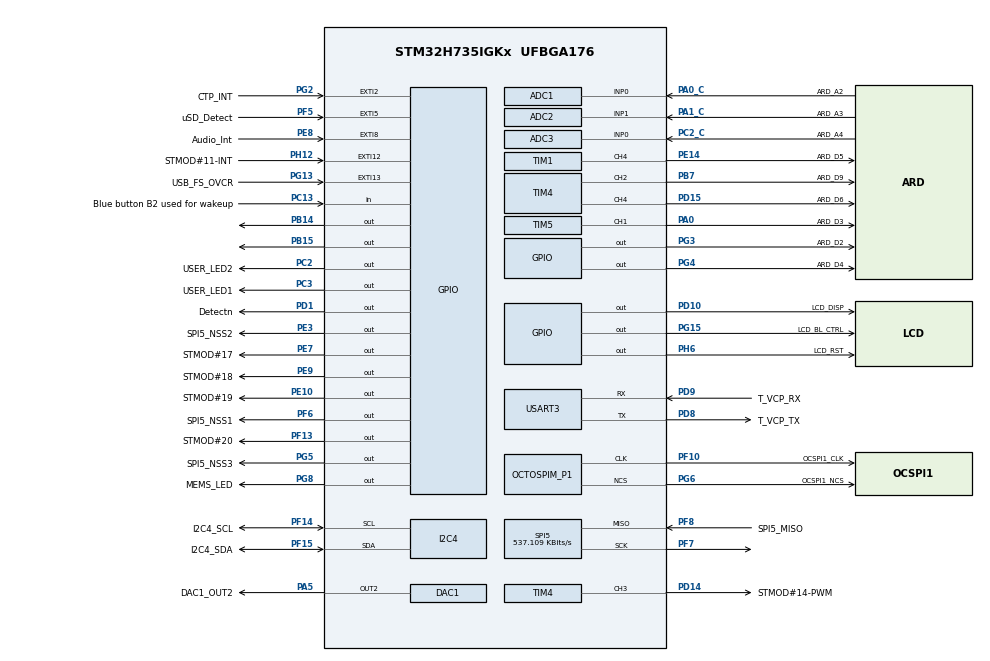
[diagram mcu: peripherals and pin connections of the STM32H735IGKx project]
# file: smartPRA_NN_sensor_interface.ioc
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ADC1.Channel-2\#ChannelRegularConversion=ADC_CHANNEL_0
ADC1.NbrOfConversionFlag=1
ADC1.OffsetNumber-2\#ChannelRegularConversion=ADC_OFFSET_NONE
ADC1.OffsetSignedSaturation-2\#ChannelRegularConversion=DISABLE
ADC1.Rank-2\#ChannelRegularConversion=1
ADC1.Resolution=ADC_RESOLUTION_10B
ADC1.SamplingTime-2\#ChannelRegularConversion=ADC_SAMPLETIME_1CYCLE_5
ADC1.master=1
ADC2.Channel-1\#ChannelRegularConversion=ADC_CHANNEL_1
ADC2.ClockPrescaler=ADC_CLOCK_ASYNC_DIV1
ADC2.NbrOfConversionFlag=1
ADC2.OffsetNumber-1\#ChannelRegularConversion=ADC_OFFSET_NONE
ADC2.OffsetSignedSaturation-1\#ChannelRegularConversion=DISABLE
ADC2.Rank-1\#ChannelRegularConversion=1
ADC2.SamplingTime-1\#ChannelRegularConversion=ADC_SAMPLETIME_1CYCLE_5
ADC3.Channel-2\#ChannelRegularConversion=ADC_CHANNEL_0
ADC3.DiscontinuousConvMode=ENABLE
ADC3.NbrOfConversionFlag=1
ADC3.OffsetNumber-2\#ChannelRegularConversion=ADC_OFFSET_NONE
ADC3.OffsetSaturation-2\#ChannelRegularConversion=DISABLE
ADC3.OffsetSign-2\#ChannelRegularConversion=ADC3_OFFSET_SIGN_NEGATIVE
ADC3.OffsetSignedSaturation-2\#ChannelRegularConversion=DISABLE
ADC3.Rank-2\#ChannelRegularConversion=1
ADC3.SamplingTime-2\#ChannelRegularConversion=ADC3_SAMPLETIME_640CYCLES_5
DAC1.DAC_Channel-DAC_OUT2=DAC_CHANNEL_2
I2C4.Timing=0x60404E72
Mcu.Family=STM32H7
Mcu.Name=STM32H735IGKx
Mcu.Package=UFBGA176
NVIC.PriorityGroup=NVIC_PRIORITYGROUP_4
NVIC.SPI5_IRQn=true\:0\:0\:true\:false\:true\:true\:true
NVIC.TIM8_UP_TIM13_IRQn=true\:1\:0\:true\:false\:true\:true\:true
NVIC.USART3_IRQn=true\:0\:0\:true\:false\:true\:true\:true
PA0.GPIO_Label=ARD_D3
PA0.Signal=S_TIM5_CH1
PA0_C.GPIO_Label=ARD_A2
PA0_C.Signal=ADCx_INP0
PA1.GPIO_Label=RMII_REF_CLK
PA1.GPIO_Speed=GPIO_SPEED_FREQ_LOW
PA1.Signal=ETH_REF_CLK
PA10.GPIO_Label=USB_FS_ID
PA10.Signal=USB_OTG_HS_ID
PA11.GPIO_Label=USB_FS_DM
PA11.Signal=USB_OTG_HS_DM
PA12.GPIO_Label=USB_FS_DP
PA12.Signal=USB_OTG_HS_DP
PA13(JTMS/SWDIO).GPIO_Label=JTMS
PA13(JTMS/SWDIO).Mode=JTAG_5_pins
PA13(JTMS/SWDIO).Signal=DEBUG_JTMS-SWDIO
PA14(JTCK/SWCLK).GPIO_Label=JTCK
PA14(JTCK/SWCLK).Mode=JTAG_5_pins
PA14(JTCK/SWCLK).Signal=DEBUG_JTCK-SWCLK
PA15(JTDI).GPIO_Label=JTDI
PA15(JTDI).Mode=JTAG_5_pins
PA15(JTDI).Signal=DEBUG_JTDI
PA1_C.GPIO_Label=ARD_A3
PA1_C.Signal=ADCx_INP1
PA2.GPIO_Label=RMII_MDIO
PA2.GPIO_Speed=GPIO_SPEED_FREQ_LOW
PA2.Signal=ETH_MDIO
PA3.GPIO_Label=LCD_B5
PA3.GPIO_Speed=GPIO_SPEED_FREQ_LOW
PA3.Signal=LTDC_B5
PA4.GPIO_Label=LCD_VSYNC
PA4.GPIO_Speed=GPIO_SPEED_FREQ_LOW
PA4.Signal=LTDC_VSYNC
PA5.GPIO_Label=DAC1_OUT2
PA5.Signal=COMP_DAC12_group
PA6.GPIO_Label=LCD_G2
PA6.GPIO_Speed=GPIO_SPEED_FREQ_LOW
PA6.Signal=LTDC_G2
PA7.GPIO_Label=RMII_CRS_DV
PA7.GPIO_Speed=GPIO_SPEED_FREQ_LOW
PA7.Signal=ETH_CRS_DV
PA8.GPIO_Label=LCD_B3
PA8.GPIO_Speed=GPIO_SPEED_FREQ_LOW
PA8.Signal=LTDC_B3
PA9.GPIO_Label=USB_FS_VBUS
PA9.Signal=USB_OTG_HS_VBUS
PB0.GPIO_Label=LCD_G1
PB0.GPIO_Speed=GPIO_SPEED_FREQ_LOW
PB0.Signal=LTDC_G1
PB1.GPIO_Label=LCD_G0
PB1.GPIO_Speed=GPIO_SPEED_FREQ_LOW
PB1.Signal=LTDC_G0
PB10.GPIO_Label=RMII_RX_ER
PB10.Signal=ETH_RX_ER
PB11.GPIO_Label=RMII_TX_EN
PB11.GPIO_Speed=GPIO_SPEED_FREQ_LOW
PB11.Signal=ETH_TX_EN
PB12.GPIO_Label=RMII_TXD0
PB12.GPIO_Speed=GPIO_SPEED_FREQ_LOW
PB12.Signal=ETH_TXD0
PB13.GPIO_Label=RMII_TXD1
PB13.GPIO_Speed=GPIO_SPEED_FREQ_LOW
PB13.Signal=ETH_TXD1
PB14.GPIO_ModeDefaultOutputPP=GPIO_MODE_OUTPUT_PP
PB14.Signal=GPIO_Output
PB15.Signal=GPIO_Output
PB2.GPIO_Label=OCSPI1_DQS
PB2.Signal=OCTOSPIM_P1_DQS
PB3(JTDO/TRACESWO).GPIO_Label=JTDO
PB3(JTDO/TRACESWO).Mode=JTAG_5_pins
PB3(JTDO/TRACESWO).Signal=DEBUG_JTDO-SWO
PB4(NJTRST).GPIO_Label=NJTRST
PB4(NJTRST).Mode=JTAG_5_pins
PB4(NJTRST).Signal=DEBUG_JTRST
PB5.GPIO_Label=FDCAN2_RX
PB5.Signal=FDCAN2_RX
PB6.GPIO_Label=FDCAN2_TX
PB6.Signal=FDCAN2_TX
PB7.GPIO_Label=ARD_D9
PB7.Signal=S_TIM4_CH2
PB8.GPIO_Label=LCD_B6
PB8.GPIO_Speed=GPIO_SPEED_FREQ_LOW
PB8.Signal=LTDC_B6
PB9.GPIO_Label=LCD_B7
PB9.GPIO_Speed=GPIO_SPEED_FREQ_LOW
PB9.Signal=LTDC_B7
PC0.GPIO_Label=ARD_A0
PC0.Signal=ADCx_INP10
PC1.GPIO_Label=RMII_MDC
PC1.GPIO_Speed=GPIO_SPEED_FREQ_LOW
PC1.Signal=ETH_MDC
PC10.GPIO_Label=SDIO1_D2
PC10.Signal=SDMMC1_D2
PC11.GPIO_Label=SDIO1_D3
PC11.Signal=SDMMC1_D3
PC12.GPIO_Label=SDIO1_CK
PC12.Signal=SDMMC1_CK
PC13.GPIO_Label=Blue button B2 used for wakeup
PC13.Signal=GPIO_Input
PC14-OSC32_IN.Mode=LSE-External-Oscillator
PC14-OSC32_IN.Signal=RCC_OSC32_IN
PC15-OSC32_OUT.Mode=LSE-External-Oscillator
PC15-OSC32_OUT.Signal=RCC_OSC32_OUT
PC2.GPIO_Label=USER_LED2
PC2.Signal=GPIO_Output
PC2_C.GPIO_Label=ARD_A4
PC2_C.Mode=IN0-Single-Ended
PC2_C.Signal=ADC3_INP0
PC3.GPIO_Label=USER_LED1
PC3.Signal=GPIO_Output
PC3_C.GPIO_Label=ARD_A5
PC3_C.Signal=ADC3_INP1
PC4.GPIO_Label=RMII_RXD0
PC4.GPIO_Speed=GPIO_SPEED_FREQ_LOW
PC4.Signal=ETH_RXD0
PC5.GPIO_Label=RMII_RXD1
PC5.GPIO_Speed=GPIO_SPEED_FREQ_LOW
PC5.Signal=ETH_RXD1
PC6.GPIO_Label=LCD_HSYNC
PC6.GPIO_Speed=GPIO_SPEED_FREQ_LOW
PC6.Signal=LTDC_HSYNC
PC7.GPIO_Label=LCD_G6
PC7.GPIO_Speed=GPIO_SPEED_FREQ_LOW
PC7.Signal=LTDC_G6
PC8.GPIO_Label=SDIO1_D0
PC8.Signal=SDMMC1_D0
PC9.GPIO_Label=SDIO1_D1
PC9.Signal=SDMMC1_D1
PD0.GPIO_Label=LCD_B1
PD0.GPIO_Speed=GPIO_SPEED_FREQ_LOW
PD0.Signal=LTDC_B1
PD1.GPIO_Label=Detectn
PD1.GPIO_PuPd=GPIO_NOPULL
PD1.Signal=GPIO_Output
PD10.GPIO_Label=LCD_DISP
PD10.GPIO_Speed=GPIO_SPEED_FREQ_LOW
PD10.Signal=GPIO_Output
PD12.GPIO_Label=OCSPI1_IO1
PD12.Signal=OCTOSPIM_P1_IO1
PD13.GPIO_Label=OCSPI1_IO3
PD13.Signal=OCTOSPIM_P1_IO3
PD14.GPIO_Label=STMOD\#14-PWM
PD14.Signal=S_TIM4_CH3
PD15.GPIO_Label=ARD_D6
PD15.Signal=S_TIM4_CH4
PD2.GPIO_Label=SDIO1_CMD
PD2.Signal=SDMMC1_CMD
PD3.GPIO_Label=LCD_G7
PD3.GPIO_Speed=GPIO_SPEED_FREQ_LOW
PD3.Signal=LTDC_G7
PD4.GPIO_Label=OCSPI1_IO4
PD4.Signal=OCTOSPIM_P1_IO4
PD5.GPIO_Label=OCSPI1_IO5
PD5.Signal=OCTOSPIM_P1_IO5
PD6.GPIO_Label=LCD_B2
PD6.GPIO_Speed=GPIO_SPEED_FREQ_LOW
PD6.Signal=LTDC_B2
PD7.GPIO_Label=OCSPI1_IO7
PD7.Signal=OCTOSPIM_P1_IO7
PD8.GPIO_Label=T_VCP_TX
PD8.GPIO_PuPd=GPIO_NOPULL
PD8.Mode=Asynchronous
PD8.Signal=USART3_TX
PD9.GPIO_Label=T_VCP_RX
PD9.GPIO_PuPd=GPIO_NOPULL
PD9.Mode=Asynchronous
PD9.Signal=USART3_RX
PE0.GPIO_Label=LCD_R0
PE0.GPIO_Speed=GPIO_SPEED_FREQ_LOW
PE0.Signal=LTDC_R0
PE1.GPIO_Label=LCD_R6
PE1.GPIO_Speed=GPIO_SPEED_FREQ_LOW
PE1.Signal=LTDC_R6
PE10.GPIO_Label=STMOD\#19
PE10.Signal=GPIO_Output
PE11.GPIO_Label=LCD_G3
PE11.GPIO_Speed=GPIO_SPEED_FREQ_LOW
PE11.Signal=LTDC_G3
PE12.GPIO_Label=LCD_B4
PE12.GPIO_Speed=GPIO_SPEED_FREQ_LOW
PE12.Signal=LTDC_B4
PE13.GPIO_Label=LCD_DE
PE13.GPIO_Speed=GPIO_SPEED_FREQ_LOW
PE13.Signal=LTDC_DE
PE14.GPIO_Label=ARD_D5
PE14.Signal=S_TIM1_CH4
PE15.GPIO_Label=LCD_R7
PE15.GPIO_Speed=GPIO_SPEED_FREQ_LOW
PE15.Signal=LTDC_R7
PE2.GPIO_Label=OCSPI1_IO2
PE2.Signal=OCTOSPIM_P1_IO2
PE3.GPIO_Label=SPI5_NSS2
PE3.Signal=GPIO_Output
PE4.GPIO_Label=SAI4_D2
PE4.Signal=SAI4_D2
PE5.GPIO_Label=SAI4_CK2
PE5.Signal=SAI4_CK2
PE6.GPIO_Label=SAI1_SD_A
PE6.Signal=SAI1_SD_A
PE7.GPIO_Label=STMOD\#17
PE7.Signal=GPIO_Output
PE8.GPIO_Label=Audio_Int
PE8.Signal=GPXTI8
PE9.GPIO_Label=STMOD\#18
PE9.Signal=GPIO_Output
PF0.GPIO_Label=OCSPI2_IO0
PF0.Signal=OCTOSPIM_P2_IO0
PF1.GPIO_Label=OCSPI2_IO1
PF1.Signal=OCTOSPIM_P2_IO1
PF10.GPIO_Label=OCSPI1_CLK
PF10.Mode=O1_P1_CLK
PF10.Signal=OCTOSPIM_P1_CLK
PF12.GPIO_Label=OCSPI2_DQS
PF12.Signal=OCTOSPIM_P2_DQS
PF13.GPIO_Label=STMOD\#20
PF13.Signal=GPIO_Output
PF14.GPIO_Label=I2C4_SCL
PF14.GPIO_Pu=GPIO_PULLUP
PF14.Mode=I2C
PF14.Signal=I2C4_SCL
PF15.GPIO_Label=I2C4_SDA
PF15.GPIO_Pu=GPIO_PULLUP
PF15.Mode=I2C
PF15.Signal=I2C4_SDA
PF2.GPIO_Label=OCSPI2_IO2
PF2.Signal=OCTOSPIM_P2_IO2
PF3.GPIO_Label=OCSPI2_IO3
PF3.Signal=OCTOSPIM_P2_IO3
PF4.GPIO_Label=OCSPI2_CLK
PF4.Signal=OCTOSPIM_P2_CLK
PF5.GPIO_Label=uSD_Detect
PF5.Signal=GPXTI5
PF6.GPIO_Label=SPI5_NSS1
PF6.Signal=GPIO_Output
PF7.GPIO_PuPd=GPIO_PULLUP
PF7.Mode=RX_Only_Simplex_Unidirect_Master
PF7.Signal=SPI5_SCK
PF8.GPIO_Label=SPI5_MISO
PF8.Mode=RX_Only_Simplex_Unidirect_Master
PF8.Signal=SPI5_MISO
PG0.GPIO_Label=OCSPI2_IO4
PG0.Signal=OCTOSPIM_P2_IO4
PG1.GPIO_Label=OCSPI2_IO5
PG1.Signal=OCTOSPIM_P2_IO5
PG10.GPIO_Label=OCSPI2_IO6
PG10.Signal=OCTOSPIM_P2_IO6
PG11.GPIO_Label=OCSPI2_IO7
PG11.Signal=OCTOSPIM_P2_IO7
PG12.GPIO_Label=OCSPI2_NCS
PG12.Signal=OCTOSPIM_P2_NCS
PG13.GPIO_Label=USB_FS_OVCR
PG13.Signal=GPXTI13
PG14.GPIO_Label=LCD_B0
PG14.GPIO_Speed=GPIO_SPEED_FREQ_LOW
PG14.Signal=LTDC_B0
PG15.GPIO_Label=LCD_BL_CTRL
PG15.GPIO_Speed=GPIO_SPEED_FREQ_LOW
PG15.Signal=GPIO_Output
PG2.GPIO_Label=CTP_INT
PG2.Signal=GPXTI2
PG3.GPIO_Label=ARD_D2
PG3.Signal=GPIO_Output
PG4.GPIO_Label=ARD_D4
PG4.Signal=GPIO_Output
PG5.GPIO_Label=SPI5_NSS3
PG5.Signal=GPIO_Output
PG6.GPIO_Label=OCSPI1_NCS
PG6.Mode=OCTOSPI1_Port1_NCS
PG6.Signal=OCTOSPIM_P1_NCS
PG7.GPIO_Label=LCD_CLK
PG7.GPIO_Speed=GPIO_SPEED_FREQ_LOW
PG7.Signal=LTDC_CLK
PG8.GPIO_Label=MEMS_LED
PG8.Signal=GPIO_Output
PG9.GPIO_Label=OCSPI1_IO6
PG9.Signal=OCTOSPIM_P1_IO6
PH0-OSC_IN.Mode=HSE-External-Oscillator
PH0-OSC_IN.Signal=RCC_OSC_IN
PH1-OSC_OUT.Mode=HSE-External-Oscillator
PH1-OSC_OUT.Signal=RCC_OSC_OUT
PH10.GPIO_Label=LCD_R4
PH10.GPIO_Speed=GPIO_SPEED_FREQ_LOW
PH10.Signal=LTDC_R4
PH11.GPIO_Label=LCD_R5
PH11.GPIO_Speed=GPIO_SPEED_FREQ_LOW
PH11.Signal=LTDC_R5
PH12.GPIO_Label=STMOD\#11-INT
PH12.Signal=GPXTI12
PH13.GPIO_Label=FDCAN1_TX
PH13.Signal=FDCAN1_TX
PH14.GPIO_Label=FDCAN1_RX
PH14.Signal=FDCAN1_RX
PH15.GPIO_Label=LCD_G4
PH15.GPIO_Speed=GPIO_SPEED_FREQ_LOW
PH15.Signal=LTDC_G4
PH2.GPIO_Label=ARD_A1
PH2.Signal=ADC3_INP13
PH3.GPIO_Label=LCD_R1
PH3.GPIO_Speed=GPIO_SPEED_FREQ_LOW
PH3.Signal=LTDC_R1
PH4.GPIO_Label=LCD_G5
PH4.GPIO_Speed=GPIO_SPEED_FREQ_LOW
PH4.Signal=LTDC_G5
PH6.GPIO_Label=LCD_RST
PH6.GPIO_Speed=GPIO_SPEED_FREQ_LOW
PH6.Signal=GPIO_Output
PH8.GPIO_Label=LCD_R2
PH8.GPIO_Speed=GPIO_SPEED_FREQ_LOW
PH8.Signal=LTDC_R2
PH9.GPIO_Label=LCD_R3
PH9.GPIO_Speed=GPIO_SPEED_FREQ_LOW
PH9.Signal=LTDC_R3
ProjectManager.HeapSize=0x200
ProjectManager.StackSize=0x400
ProjectManager.TargetToolchain=STM32CubeIDE
RCC.ADCFreq_Value=80000000
RCC.APB1Freq_Value=137500000
RCC.APB2Freq_Value=137500000
RCC.APB3Freq_Value=137500000
RCC.APB4Freq_Value=137500000
RCC.CortexFreq_Value=550000000
RCC.D1PPRE=RCC_APB3_DIV2
RCC.D2PPRE1=RCC_APB1_DIV2
RCC.D2PPRE2=RCC_APB2_DIV2
RCC.D3PPRE=RCC_APB4_DIV2
RCC.DIVM1=5
RCC.DIVM2=5
RCC.DIVN1=110
RCC.DIVN2=80
RCC.DIVP1=1
RCC.DIVP2=5
RCC.DIVQ1=4
RCC.HCLKFreq_Value=275000000
RCC.HPRE=RCC_HCLK_DIV2
RCC.PLL1_VCI_Range-AdvancedSettings=RCC_PLL1VCIRANGE_3
RCC.PLL1_VCO_SEL-AdvancedSettings=RCC_PLL1VCOMEDIUM
RCC.PLL2FRACN=0
RCC.PLL2_VCI_Range-AdvancedSettings=RCC_PLL2VCIRANGE_0
RCC.PLL2_VCO_SEL-AdvancedSettings=RCC_PLL2VCOMEDIUM
RCC.PLL3FRACN=0
RCC.PLL3_VCO_SEL-AdvancedSettings=RCC_PLL3VCOMEDIUM
RCC.PLLFRACN=0
RCC.PLLSourceVirtual=RCC_PLLSOURCE_HSE
RCC.SYSCLKFreq_VALUE=550000000
RCC.SYSCLKSource=RCC_SYSCLKSOURCE_PLLCLK
RCC.USBCLockSelection=RCC_USBCLKSOURCE_HSI48
RCC.USBFreq_Value=48000000
SH.ADCx_INP0.0=ADC1_INP0,IN0-Single-Ended
SH.ADCx_INP1.0=ADC2_INP1,IN1-Single-Ended
SH.ADCx_INP10.0=ADC1_INP10
SH.COMP_DAC12_group.0=DAC1_OUT2,DAC_OUT2
SH.S_TIM1_CH4.0=TIM1_CH4,PWM Generation4 CH4
SH.S_TIM4_CH2.0=TIM4_CH2,PWM Generation2 CH2
SH.S_TIM4_CH3.0=TIM4_CH3,PWM Generation3 CH3
SH.S_TIM4_CH4.0=TIM4_CH4,PWM Generation4 CH4
SH.S_TIM5_CH1.0=TIM5_CH1,PWM Generation1 CH1
SPI5.BaudRatePrescaler=SPI_BAUDRATEPRESCALER_256
SPI5.CalculateBaudRate=537.109 KBits/s
SPI5.DataSize=SPI_DATASIZE_16BIT
SPI5.Direction=SPI_DIRECTION_2LINES_RXONLY
SPI5.Mode=SPI_MODE_MASTER
SPI5.VirtualType=VM_MASTER
TIM1.Channel-PWM\ Generation4\ CH4=TIM_CHANNEL_4
TIM13.AutoReloadPreload=TIM_AUTORELOAD_PRELOAD_ENABLE
TIM13.Period=1000-1
TIM13.Prescaler=275 - 1
TIM4.Channel-PWM\ Generation2\ CH2=TIM_CHANNEL_2
TIM4.Channel-PWM\ Generation3\ CH3=TIM_CHANNEL_3
TIM4.Channel-PWM\ Generation4\ CH4=TIM_CHANNEL_4
TIM5.Channel-PWM\ Generation1\ CH1=TIM_CHANNEL_1
USART3.VirtualMode-Asynchronous=VM_ASYNC
VP_OCTOSPI1_VS_dual.Mode=single_mode
VP_TIM13_VS_ClockSourceINT.Mode=Enable_Timer
board=STM32H735G-DK

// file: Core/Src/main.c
/* USER CODE BEGIN Header */
/**
  ******************************************************************************
  * @file           : main.c
  * @brief          : Main program body
  ******************************************************************************
  * @attention
  *
  * <h2><center>&copy; Copyright (c) 2021 STMicroelectronics.
  * All rights reserved.</center></h2>
  *
  * This software component is licensed by ST under BSD 3-Clause license,
  * the "License"; You may not use this file except in compliance with the
  * License. You may obtain a copy of the License at:
  *                        opensource.org/licenses/BSD-3-Clause
  *
  ******************************************************************************
  */
/* USER CODE END Header */
#include "main.h"

/* USER CODE BEGIN Includes */
#include "neuralnet.h"
#include "nnconfig.h"
/* USER CODE END Includes */

/* USER CODE BEGIN PD */
#ifdef __GNUC__
/* With GCC, small printf (option LD Linker->Libraries->Small printf
   set to 'Yes') calls __io_putchar() */
#define PUTCHAR_PROTOTYPE int __io_putchar(int ch)
#else
#define PUTCHAR_PROTOTYPE int fputc(int ch, FILE *f)
#endif /* __GNUC__ */
/* USER CODE END PD */

ADC_HandleTypeDef hadc1;
ADC_HandleTypeDef hadc2;
ADC_HandleTypeDef hadc3;

DAC_HandleTypeDef hdac1;

I2C_HandleTypeDef hi2c4;

OSPI_HandleTypeDef hospi1;

SPI_HandleTypeDef hspi5;

TIM_HandleTypeDef htim1;
TIM_HandleTypeDef htim4;
TIM_HandleTypeDef htim5;
TIM_HandleTypeDef htim13;

UART_HandleTypeDef huart3;

/* USER CODE BEGIN PV */

PUTCHAR_PROTOTYPE
{
  /* Place your implementation of fputc here */
  /* e.g. write a character to the USART1 and Loop until the end of transmission */
  HAL_UART_Transmit(&huart3, (uint8_t *)&ch, 1, 0xFFFF);

  return ch;
}
/* USER CODE END PV */

void SystemClock_Config(void);
void PeriphCommonClock_Config(void);
static void MX_GPIO_Init(void);
static void MX_ADC1_Init(void);
static void MX_ADC3_Init(void);
static void MX_DAC1_Init(void);
static void MX_I2C4_Init(void);
static void MX_OCTOSPI1_Init(void);
static void MX_TIM1_Init(void);
static void MX_TIM4_Init(void);
static void MX_TIM5_Init(void);
static void MX_USART3_UART_Init(void);
static void MX_SPI5_Init(void);
static void MX_TIM13_Init(void);
static void MX_ADC2_Init(void);
/* USER CODE BEGIN PFP */

//Sensor Data Buffer
float voltage_value = 0;
float temp_value = 0 ;
float current_value = 0;
uint16_t buffer_rx1;
_Bool flag_current, flag;
uint32_t adc_value2;

//Counter Variables
uint16_t counter = 0;
uint32_t start, end;
uint32_t start_, end_;
uint32_t counter_for_timing = 0;

//average responsive time Variables
uint32_t temp_exec = 0;
uint32_t voltage_exec = 0;
uint32_t current_exec = 0;
uint32_t NN_exec = 0;
uint32_t Total_exec = 0;

// Neural Net Model Variables
Model* model;
Linear* l1;;
Linear* l2;
Linear* l3;

//
#define DATA_DEBUG 1
#define TIME_DEBUG 1
/* USER CODE END PFP */

/* USER CODE BEGIN 0 */
void print_data(){

	printf("--------------------\r\n");
	printf("Voltage : %f(V)\r\n", voltage_value);
	printf("temperature : %f('C)\r\n", temp_value);
	printf("ADC value : %ld -> current : %f(mA)\r\n", adc_value2, current_value);
}

void HAL_SPI_RxCpltCallback(SPI_HandleTypeDef *hspi)
{
	HAL_GPIO_WritePin(SPI5_NSS1_GPIO_Port, SPI5_NSS1_Pin, GPIO_PIN_SET); // deactivate
	flag = 1;
	current_value = (buffer_rx1 - 2048) * 1000 / 89.95;
}

//Timer interrupted every 1ms
void HAL_TIM_PeriodElapsedCallback(TIM_HandleTypeDef *htim)
{

	uint32_t adc_value;

	uint16_t print_interval = 100;

	if (htim->Instance == TIM13)
	{
		start = htim->Instance->CNT;
		counter_for_timing++;

		counter = (counter + 1) % print_interval;

		//Get Voltage sensor value
		start_ = htim->Instance->CNT;
		HAL_ADC_Start(&hadc1);
		HAL_ADC_PollForConversion(&hadc1, 1);
		adc_value = HAL_ADC_GetValue(&hadc1);
		HAL_ADC_Stop(&hadc1);
		end_ = htim->Instance->CNT;

		voltage_exec += (end_ - start_);

		voltage_value =  (float)(adc_value - 37) * 5 * 4 / 1024;

		//Get temperature sensor value
		start_ = htim->Instance->CNT;
		HAL_ADC_Start(&hadc3);
		HAL_ADC_PollForConversion(&hadc3, 1);
		adc_value = HAL_ADC_GetValue(&hadc3);
		HAL_ADC_Stop(&hadc3);
		end_ = htim->Instance->CNT;
		temp_exec += (end_ - start_);

		temp_value = (float)(adc_value *330) / 4095;

		//Get current sensor value
		start_ = htim->Instance->CNT;
		HAL_ADC_Start(&hadc2);
		HAL_ADC_PollForConversion(&hadc2, 1);
		adc_value2 = HAL_ADC_GetValue(&hadc2);
		HAL_ADC_Stop(&hadc2);
		current_value = (float)(adc_value2* 3.3) / 65535 ;

		end_ = htim->Instance->CNT;
		current_exec += (end_ - start_);

		start_ = htim->Instance->CNT;
		float sample[4] = {current_value, voltage_value, temp_value, 0 };
		float* result = forward(model, sample);
		end_ = htim->Instance->CNT;

		NN_exec += (end_ - start_);

		Total_exec += (end_ - start);
		if(DATA_DEBUG){
			if(counter == 0){
				print_data();
				printf("NeuralNet Output : ");
				for (int i = 0; i < l3->out_dim; i++) {
					printf("%d : %f 	", i, result[i]);
				}
				printf("\r\n--------------------\r\n\r\n");
			}
		}

		if(TIME_DEBUG){

			if(counter_for_timing == 1000){

				printf("\r\n");
				printf("-------------------------------------\r\n");
				printf("current sensor response time : %f(us)\r\n", (float)current_exec /1000 );
				printf("ADC voltage sensor response time : %f(us)\r\n", (float)voltage_exec / 1000);
				printf("ADC temperature sensor response time : %f(us)\r\n", (float)temp_exec / 1000);
				printf("Neural Net Processing response time : %f(us)\r\n", (float)NN_exec / 1000);
				printf("Total response time : %f(us)\r\n", (float)Total_exec / 1000);
				printf("--------------------------------------\r\n\r\n");

				current_exec = 0;
				temp_exec = 0;
				voltage_exec =0;
				NN_exec =0 ;
				Total_exec = 0;
				counter_for_timing =0;
			}
		}
	}

}

/* USER CODE END 0 */

int main(void)
{

  /* MCU Configuration--------------------------------------------------------*/

  /* Reset of all peripherals, Initializes the Flash interface and the Systick. */
  HAL_Init();

  /* Configure the system clock */
  SystemClock_Config();

/* Configure the peripherals common clocks */
  PeriphCommonClock_Config();

  /* Initialize all configured peripherals */
  MX_GPIO_Init();
  MX_ADC1_Init();
  MX_ADC3_Init();
  MX_DAC1_Init();
  MX_I2C4_Init();
  MX_OCTOSPI1_Init();
  MX_TIM1_Init();
  MX_TIM4_Init();
  MX_TIM5_Init();
  MX_USART3_UART_Init();
  MX_SPI5_Init();
  MX_TIM13_Init();
  MX_ADC2_Init();

  /* Infinite loop */
  /* USER CODE BEGIN WHILE */
  HAL_GPIO_WritePin(SPI5_NSS1_GPIO_Port, SPI5_NSS1_Pin, GPIO_PIN_SET); // deactivate

  model = (Model*)malloc(sizeof(Model));
  Model_construct(model, linear_num);

  l1 = (Linear*)malloc(sizeof(Linear));
  l2 = (Linear*)malloc(sizeof(Linear));
  l3 = (Linear*)malloc(sizeof(Linear));

  Linear_construct(l1, linear1_out_dim, linear1_in_dim, linear1_bias, RELU);
  l1->weight = (float**)malloc(sizeof(float*) * linear1_out_dim);
  for (int i = 0; i < linear1_out_dim; i++) {
  	l1->weight[i] = linear1_weight[i];
  }
  Model_append(model, l1, 1);

  Linear_construct(l2, linear2_out_dim, linear2_in_dim, linear2_bias, RELU);
  l2->weight = (float**)malloc(sizeof(float*) * linear2_out_dim);
  for (int i = 0; i < linear2_out_dim; i++) {
  	l2->weight[i] = linear2_weight[i];
  }
  Model_append(model, l2, 2);

  Linear_construct(l3, linear3_out_dim, linear3_in_dim, linear3_bias, SIGMOID);
  l3->weight = (float**)malloc(sizeof(float*) * linear3_out_dim);
  for (int i = 0; i < linear3_out_dim; i++) {
	  l3->weight[i] = linear3_weight[i];
  }
  Model_append(model, l3, 3);

  HAL_TIM_Base_Start_IT(&htim13);
  while (1)
  {
    /* USER CODE END WHILE */

  }
}

void SystemClock_Config(void)
{
  RCC_OscInitTypeDef RCC_OscInitStruct = {0};
  RCC_ClkInitTypeDef RCC_ClkInitStruct = {0};

  /** Supply configuration update enable
  */
  HAL_PWREx_ConfigSupply(PWR_DIRECT_SMPS_SUPPLY);
  /** Configure the main internal regulator output voltage
  */
  __HAL_PWR_VOLTAGESCALING_CONFIG(PWR_REGULATOR_VOLTAGE_SCALE0);

  while(!__HAL_PWR_GET_FLAG(PWR_FLAG_VOSRDY)) {}
  /** Macro to configure the PLL clock source
  */
  __HAL_RCC_PLL_PLLSOURCE_CONFIG(RCC_PLLSOURCE_HSE);
  /** Initializes the RCC Oscillators according to the specified parameters
  * in the RCC_OscInitTypeDef structure.
  */
  RCC_OscInitStruct.OscillatorType = RCC_OSCILLATORTYPE_HSE;
  RCC_OscInitStruct.HSEState = RCC_HSE_ON;
  RCC_OscInitStruct.PLL.PLLState = RCC_PLL_ON;
  RCC_OscInitStruct.PLL.PLLSource = RCC_PLLSOURCE_HSE;
  RCC_OscInitStruct.PLL.PLLM = 5;
  RCC_OscInitStruct.PLL.PLLN = 110;
  RCC_OscInitStruct.PLL.PLLP = 1;
  RCC_OscInitStruct.PLL.PLLQ = 4;
  RCC_OscInitStruct.PLL.PLLR = 2;
  RCC_OscInitStruct.PLL.PLLRGE = RCC_PLL1VCIRANGE_2;
  RCC_OscInitStruct.PLL.PLLVCOSEL = RCC_PLL1VCOWIDE;
  RCC_OscInitStruct.PLL.PLLFRACN = 0;
  if (HAL_RCC_OscConfig(&RCC_OscInitStruct) != HAL_OK)
  {
    Error_Handler();
  }
  /** Initializes the CPU, AHB and APB buses clocks
  */
  RCC_ClkInitStruct.ClockType = RCC_CLOCKTYPE_HCLK|RCC_CLOCKTYPE_SYSCLK
                              |RCC_CLOCKTYPE_PCLK1|RCC_CLOCKTYPE_PCLK2
                              |RCC_CLOCKTYPE_D3PCLK1|RCC_CLOCKTYPE_D1PCLK1;
  RCC_ClkInitStruct.SYSCLKSource = RCC_SYSCLKSOURCE_PLLCLK;
  RCC_ClkInitStruct.SYSCLKDivider = RCC_SYSCLK_DIV1;
  RCC_ClkInitStruct.AHBCLKDivider = RCC_HCLK_DIV2;
  RCC_ClkInitStruct.APB3CLKDivider = RCC_APB3_DIV2;
  RCC_ClkInitStruct.APB1CLKDivider = RCC_APB1_DIV2;
  RCC_ClkInitStruct.APB2CLKDivider = RCC_APB2_DIV2;
  RCC_ClkInitStruct.APB4CLKDivider = RCC_APB4_DIV2;

  if (HAL_RCC_ClockConfig(&RCC_ClkInitStruct, FLASH_LATENCY_3) != HAL_OK)
  {
    Error_Handler();
  }
}

void PeriphCommonClock_Config(void)
{
  RCC_PeriphCLKInitTypeDef PeriphClkInitStruct = {0};

  /** Initializes the peripherals clock
  */
  PeriphClkInitStruct.PeriphClockSelection = RCC_PERIPHCLK_ADC;
  PeriphClkInitStruct.PLL2.PLL2M = 5;
  PeriphClkInitStruct.PLL2.PLL2N = 80;
  PeriphClkInitStruct.PLL2.PLL2P = 5;
  PeriphClkInitStruct.PLL2.PLL2Q = 2;
  PeriphClkInitStruct.PLL2.PLL2R = 2;
  PeriphClkInitStruct.PLL2.PLL2RGE = RCC_PLL2VCIRANGE_2;
  PeriphClkInitStruct.PLL2.PLL2VCOSEL = RCC_PLL2VCOWIDE;
  PeriphClkInitStruct.PLL2.PLL2FRACN = 0;
  PeriphClkInitStruct.AdcClockSelection = RCC_ADCCLKSOURCE_PLL2;
  if (HAL_RCCEx_PeriphCLKConfig(&PeriphClkInitStruct) != HAL_OK)
  {
    Error_Handler();
  }
}

static void MX_ADC1_Init(void)
{

  ADC_MultiModeTypeDef multimode = {0};
  ADC_ChannelConfTypeDef sConfig = {0};

  /** Common config
  */
  hadc1.Instance = ADC1;
  hadc1.Init.ClockPrescaler = ADC_CLOCK_ASYNC_DIV1;
  hadc1.Init.Resolution = ADC_RESOLUTION_10B;
  hadc1.Init.ScanConvMode = ADC_SCAN_DISABLE;
  hadc1.Init.EOCSelection = ADC_EOC_SINGLE_CONV;
  hadc1.Init.LowPowerAutoWait = DISABLE;
  hadc1.Init.ContinuousConvMode = DISABLE;
  hadc1.Init.NbrOfConversion = 1;
  hadc1.Init.DiscontinuousConvMode = DISABLE;
  hadc1.Init.ExternalTrigConv = ADC_SOFTWARE_START;
  hadc1.Init.ExternalTrigConvEdge = ADC_EXTERNALTRIGCONVEDGE_NONE;
  hadc1.Init.ConversionDataManagement = ADC_CONVERSIONDATA_DR;
  hadc1.Init.Overrun = ADC_OVR_DATA_PRESERVED;
  hadc1.Init.LeftBitShift = ADC_LEFTBITSHIFT_NONE;
  hadc1.Init.OversamplingMode = DISABLE;
  if (HAL_ADC_Init(&hadc1) != HAL_OK)
  {
    Error_Handler();
  }
  /** Configure the ADC multi-mode
  */
  multimode.Mode = ADC_MODE_INDEPENDENT;
  if (HAL_ADCEx_MultiModeConfigChannel(&hadc1, &multimode) != HAL_OK)
  {
    Error_Handler();
  }
  /** Configure Regular Channel
  */
  sConfig.Channel = ADC_CHANNEL_0;
  sConfig.Rank = ADC_REGULAR_RANK_1;
  sConfig.SamplingTime = ADC_SAMPLETIME_1CYCLE_5;
  sConfig.SingleDiff = ADC_SINGLE_ENDED;
  sConfig.OffsetNumber = ADC_OFFSET_NONE;
  sConfig.Offset = 0;
  sConfig.OffsetSignedSaturation = DISABLE;
  if (HAL_ADC_ConfigChannel(&hadc1, &sConfig) != HAL_OK)
  {
    Error_Handler();
  }

}

static void MX_ADC2_Init(void)
{

  ADC_ChannelConfTypeDef sConfig = {0};

  /** Common config
  */
  hadc2.Instance = ADC2;
  hadc2.Init.ClockPrescaler = ADC_CLOCK_ASYNC_DIV1;
  hadc2.Init.Resolution = ADC_RESOLUTION_16B;
  hadc2.Init.ScanConvMode = ADC_SCAN_DISABLE;
  hadc2.Init.EOCSelection = ADC_EOC_SINGLE_CONV;
  hadc2.Init.LowPowerAutoWait = DISABLE;
  hadc2.Init.ContinuousConvMode = DISABLE;
  hadc2.Init.NbrOfConversion = 1;
  hadc2.Init.DiscontinuousConvMode = DISABLE;
  hadc2.Init.ExternalTrigConv = ADC_SOFTWARE_START;
  hadc2.Init.ExternalTrigConvEdge = ADC_EXTERNALTRIGCONVEDGE_NONE;
  hadc2.Init.ConversionDataManagement = ADC_CONVERSIONDATA_DR;
  hadc2.Init.Overrun = ADC_OVR_DATA_PRESERVED;
  hadc2.Init.LeftBitShift = ADC_LEFTBITSHIFT_NONE;
  hadc2.Init.OversamplingMode = DISABLE;
  if (HAL_ADC_Init(&hadc2) != HAL_OK)
  {
    Error_Handler();
  }
  /** Configure Regular Channel
  */
  sConfig.Channel = ADC_CHANNEL_1;
  sConfig.Rank = ADC_REGULAR_RANK_1;
  sConfig.SamplingTime = ADC_SAMPLETIME_1CYCLE_5;
  sConfig.SingleDiff = ADC_SINGLE_ENDED;
  sConfig.OffsetNumber = ADC_OFFSET_NONE;
  sConfig.Offset = 0;
  sConfig.OffsetSignedSaturation = DISABLE;
  if (HAL_ADC_ConfigChannel(&hadc2, &sConfig) != HAL_OK)
  {
    Error_Handler();
  }

}

static void MX_ADC3_Init(void)
{

  ADC_ChannelConfTypeDef sConfig = {0};

  /** Common config
  */
  hadc3.Instance = ADC3;
  hadc3.Init.ClockPrescaler = ADC_CLOCK_ASYNC_DIV1;
  hadc3.Init.Resolution = ADC_RESOLUTION_12B;
  hadc3.Init.DataAlign = ADC3_DATAALIGN_RIGHT;
  hadc3.Init.ScanConvMode = ADC_SCAN_DISABLE;
  hadc3.Init.EOCSelection = ADC_EOC_SINGLE_CONV;
  hadc3.Init.LowPowerAutoWait = DISABLE;
  hadc3.Init.ContinuousConvMode = DISABLE;
  hadc3.Init.NbrOfConversion = 1;
  hadc3.Init.DiscontinuousConvMode = ENABLE;
  hadc3.Init.NbrOfDiscConversion = 1;
  hadc3.Init.ExternalTrigConv = ADC_SOFTWARE_START;
  hadc3.Init.ExternalTrigConvEdge = ADC_EXTERNALTRIGCONVEDGE_NONE;
  hadc3.Init.DMAContinuousRequests = DISABLE;
  hadc3.Init.SamplingMode = ADC_SAMPLING_MODE_NORMAL;
  hadc3.Init.ConversionDataManagement = ADC_CONVERSIONDATA_DR;
  hadc3.Init.Overrun = ADC_OVR_DATA_PRESERVED;
  hadc3.Init.LeftBitShift = ADC_LEFTBITSHIFT_NONE;
  hadc3.Init.OversamplingMode = DISABLE;
  if (HAL_ADC_Init(&hadc3) != HAL_OK)
  {
    Error_Handler();
  }
  /** Configure Regular Channel
  */
  sConfig.Channel = ADC_CHANNEL_0;
  sConfig.Rank = ADC_REGULAR_RANK_1;
  sConfig.SamplingTime = ADC3_SAMPLETIME_640CYCLES_5;
  sConfig.SingleDiff = ADC_SINGLE_ENDED;
  sConfig.OffsetNumber = ADC_OFFSET_NONE;
  sConfig.Offset = 0;
  sConfig.OffsetSignedSaturation = DISABLE;
  sConfig.OffsetSign = ADC3_OFFSET_SIGN_NEGATIVE;
  sConfig.OffsetSaturation = DISABLE;
  if (HAL_ADC_ConfigChannel(&hadc3, &sConfig) != HAL_OK)
  {
    Error_Handler();
  }

}

static void MX_DAC1_Init(void)
{

  DAC_ChannelConfTypeDef sConfig = {0};

  /** DAC Initialization
  */
  hdac1.Instance = DAC1;
  if (HAL_DAC_Init(&hdac1) != HAL_OK)
  {
    Error_Handler();
  }
  /** DAC channel OUT2 config
  */
  sConfig.DAC_SampleAndHold = DAC_SAMPLEANDHOLD_DISABLE;
  sConfig.DAC_Trigger = DAC_TRIGGER_NONE;
  sConfig.DAC_OutputBuffer = DAC_OUTPUTBUFFER_ENABLE;
  sConfig.DAC_ConnectOnChipPeripheral = DAC_CHIPCONNECT_DISABLE;
  sConfig.DAC_UserTrimming = DAC_TRIMMING_FACTORY;
  if (HAL_DAC_ConfigChannel(&hdac1, &sConfig, DAC_CHANNEL_2) != HAL_OK)
  {
    Error_Handler();
  }

}

static void MX_I2C4_Init(void)
{

  hi2c4.Instance = I2C4;
  hi2c4.Init.Timing = 0x60404E72;
  hi2c4.Init.OwnAddress1 = 0;
  hi2c4.Init.AddressingMode = I2C_ADDRESSINGMODE_7BIT;
  hi2c4.Init.DualAddressMode = I2C_DUALADDRESS_DISABLE;
  hi2c4.Init.OwnAddress2 = 0;
  hi2c4.Init.OwnAddress2Masks = I2C_OA2_NOMASK;
  hi2c4.Init.GeneralCallMode = I2C_GENERALCALL_DISABLE;
  hi2c4.Init.NoStretchMode = I2C_NOSTRETCH_DISABLE;
  if (HAL_I2C_Init(&hi2c4) != HAL_OK)
  {
    Error_Handler();
  }
  /** Configure Analogue filter
  */
  if (HAL_I2CEx_ConfigAnalogFilter(&hi2c4, I2C_ANALOGFILTER_ENABLE) != HAL_OK)
  {
    Error_Handler();
  }
  /** Configure Digital filter
  */
  if (HAL_I2CEx_ConfigDigitalFilter(&hi2c4, 0) != HAL_OK)
  {
    Error_Handler();
  }

}

static void MX_OCTOSPI1_Init(void)
{

  OSPIM_CfgTypeDef sOspiManagerCfg = {0};

  /* OCTOSPI1 parameter configuration*/
  hospi1.Instance = OCTOSPI1;
  hospi1.Init.FifoThreshold = 1;
  hospi1.Init.DualQuad = HAL_OSPI_DUALQUAD_DISABLE;
  hospi1.Init.MemoryType = HAL_OSPI_MEMTYPE_MICRON;
  hospi1.Init.DeviceSize = 32;
  hospi1.Init.ChipSelectHighTime = 1;
  hospi1.Init.FreeRunningClock = HAL_OSPI_FREERUNCLK_DISABLE;
  hospi1.Init.ClockMode = HAL_OSPI_CLOCK_MODE_0;
  hospi1.Init.WrapSize = HAL_OSPI_WRAP_NOT_SUPPORTED;
  hospi1.Init.ClockPrescaler = 1;
  hospi1.Init.SampleShifting = HAL_OSPI_SAMPLE_SHIFTING_NONE;
  hospi1.Init.DelayHoldQuarterCycle = HAL_OSPI_DHQC_DISABLE;
  hospi1.Init.ChipSelectBoundary = 1;
  hospi1.Init.ClkChipSelectHighTime = 0;
  hospi1.Init.DelayBlockBypass = HAL_OSPI_DELAY_BLOCK_BYPASSED;
  hospi1.Init.MaxTran = 0;
  hospi1.Init.Refresh = 0;
  if (HAL_OSPI_Init(&hospi1) != HAL_OK)
  {
    Error_Handler();
  }
  sOspiManagerCfg.ClkPort = 1;
  sOspiManagerCfg.NCSPort = 1;
  if (HAL_OSPIM_Config(&hospi1, &sOspiManagerCfg, HAL_OSPI_TIMEOUT_DEFAULT_VALUE) != HAL_OK)
  {
    Error_Handler();
  }

}

static void MX_SPI5_Init(void)
{

  /* SPI5 parameter configuration*/
  hspi5.Instance = SPI5;
  hspi5.Init.Mode = SPI_MODE_MASTER;
  hspi5.Init.Direction = SPI_DIRECTION_2LINES_RXONLY;
  hspi5.Init.DataSize = SPI_DATASIZE_16BIT;
  hspi5.Init.CLKPolarity = SPI_POLARITY_LOW;
  hspi5.Init.CLKPhase = SPI_PHASE_1EDGE;
  hspi5.Init.NSS = SPI_NSS_SOFT;
  hspi5.Init.BaudRatePrescaler = SPI_BAUDRATEPRESCALER_256;
  hspi5.Init.FirstBit = SPI_FIRSTBIT_MSB;
  hspi5.Init.TIMode = SPI_TIMODE_DISABLE;
  hspi5.Init.CRCCalculation = SPI_CRCCALCULATION_DISABLE;
  hspi5.Init.CRCPolynomial = 0x0;
  hspi5.Init.NSSPMode = SPI_NSS_PULSE_ENABLE;
  hspi5.Init.NSSPolarity = SPI_NSS_POLARITY_LOW;
  hspi5.Init.FifoThreshold = SPI_FIFO_THRESHOLD_01DATA;
  hspi5.Init.TxCRCInitializationPattern = SPI_CRC_INITIALIZATION_ALL_ZERO_PATTERN;
  hspi5.Init.RxCRCInitializationPattern = SPI_CRC_INITIALIZATION_ALL_ZERO_PATTERN;
  hspi5.Init.MasterSSIdleness = SPI_MASTER_SS_IDLENESS_00CYCLE;
  hspi5.Init.MasterInterDataIdleness = SPI_MASTER_INTERDATA_IDLENESS_00CYCLE;
  hspi5.Init.MasterReceiverAutoSusp = SPI_MASTER_RX_AUTOSUSP_DISABLE;
  hspi5.Init.MasterKeepIOState = SPI_MASTER_KEEP_IO_STATE_DISABLE;
  hspi5.Init.IOSwap = SPI_IO_SWAP_DISABLE;
  if (HAL_SPI_Init(&hspi5) != HAL_OK)
  {
    Error_Handler();
  }

}

static void MX_TIM1_Init(void)
{

  TIM_MasterConfigTypeDef sMasterConfig = {0};
  TIM_OC_InitTypeDef sConfigOC = {0};
  TIM_BreakDeadTimeConfigTypeDef sBreakDeadTimeConfig = {0};

  htim1.Instance = TIM1;
  htim1.Init.Prescaler = 0;
  htim1.Init.CounterMode = TIM_COUNTERMODE_UP;
  htim1.Init.Period = 65535;
  htim1.Init.ClockDivision = TIM_CLOCKDIVISION_DIV1;
  htim1.Init.RepetitionCounter = 0;
  htim1.Init.AutoReloadPreload = TIM_AUTORELOAD_PRELOAD_DISABLE;
  if (HAL_TIM_PWM_Init(&htim1) != HAL_OK)
  {
    Error_Handler();
  }
  sMasterConfig.MasterOutputTrigger = TIM_TRGO_RESET;
  sMasterConfig.MasterOutputTrigger2 = TIM_TRGO2_RESET;
  sMasterConfig.MasterSlaveMode = TIM_MASTERSLAVEMODE_DISABLE;
  if (HAL_TIMEx_MasterConfigSynchronization(&htim1, &sMasterConfig) != HAL_OK)
  {
    Error_Handler();
  }
  sConfigOC.OCMode = TIM_OCMODE_PWM1;
  sConfigOC.Pulse = 0;
  sConfigOC.OCPolarity = TIM_OCPOLARITY_HIGH;
  sConfigOC.OCFastMode = TIM_OCFAST_DISABLE;
  sConfigOC.OCIdleState = TIM_OCIDLESTATE_RESET;
  sConfigOC.OCNIdleState = TIM_OCNIDLESTATE_RESET;
  if (HAL_TIM_PWM_ConfigChannel(&htim1, &sConfigOC, TIM_CHANNEL_4) != HAL_OK)
  {
    Error_Handler();
  }
  sBreakDeadTimeConfig.OffStateRunMode = TIM_OSSR_DISABLE;
  sBreakDeadTimeConfig.OffStateIDLEMode = TIM_OSSI_DISABLE;
  sBreakDeadTimeConfig.LockLevel = TIM_LOCKLEVEL_OFF;
  sBreakDeadTimeConfig.DeadTime = 0;
  sBreakDeadTimeConfig.BreakState = TIM_BREAK_DISABLE;
  sBreakDeadTimeConfig.BreakPolarity = TIM_BREAKPOLARITY_HIGH;
  sBreakDeadTimeConfig.BreakFilter = 0;
  sBreakDeadTimeConfig.Break2State = TIM_BREAK2_DISABLE;
  sBreakDeadTimeConfig.Break2Polarity = TIM_BREAK2POLARITY_HIGH;
  sBreakDeadTimeConfig.Break2Filter = 0;
  sBreakDeadTimeConfig.AutomaticOutput = TIM_AUTOMATICOUTPUT_DISABLE;
  if (HAL_TIMEx_ConfigBreakDeadTime(&htim1, &sBreakDeadTimeConfig) != HAL_OK)
  {
    Error_Handler();
  }
  HAL_TIM_MspPostInit(&htim1);

}

static void MX_TIM4_Init(void)
{

  TIM_MasterConfigTypeDef sMasterConfig = {0};
  TIM_OC_InitTypeDef sConfigOC = {0};

  htim4.Instance = TIM4;
  htim4.Init.Prescaler = 0;
  htim4.Init.CounterMode = TIM_COUNTERMODE_UP;
  htim4.Init.Period = 65535;
  htim4.Init.ClockDivision = TIM_CLOCKDIVISION_DIV1;
  htim4.Init.AutoReloadPreload = TIM_AUTORELOAD_PRELOAD_DISABLE;
  if (HAL_TIM_PWM_Init(&htim4) != HAL_OK)
  {
    Error_Handler();
  }
  sMasterConfig.MasterOutputTrigger = TIM_TRGO_RESET;
  sMasterConfig.MasterSlaveMode = TIM_MASTERSLAVEMODE_DISABLE;
  if (HAL_TIMEx_MasterConfigSynchronization(&htim4, &sMasterConfig) != HAL_OK)
  {
    Error_Handler();
  }
  sConfigOC.OCMode = TIM_OCMODE_PWM1;
  sConfigOC.Pulse = 0;
  sConfigOC.OCPolarity = TIM_OCPOLARITY_HIGH;
  sConfigOC.OCFastMode = TIM_OCFAST_DISABLE;
  if (HAL_TIM_PWM_ConfigChannel(&htim4, &sConfigOC, TIM_CHANNEL_2) != HAL_OK)
  {
    Error_Handler();
  }
  if (HAL_TIM_PWM_ConfigChannel(&htim4, &sConfigOC, TIM_CHANNEL_3) != HAL_OK)
  {
    Error_Handler();
  }
  if (HAL_TIM_PWM_ConfigChannel(&htim4, &sConfigOC, TIM_CHANNEL_4) != HAL_OK)
  {
    Error_Handler();
  }
  HAL_TIM_MspPostInit(&htim4);

}

static void MX_TIM5_Init(void)
{

  TIM_MasterConfigTypeDef sMasterConfig = {0};
  TIM_OC_InitTypeDef sConfigOC = {0};

  htim5.Instance = TIM5;
  htim5.Init.Prescaler = 0;
  htim5.Init.CounterMode = TIM_COUNTERMODE_UP;
  htim5.Init.Period = 4294967295;
  htim5.Init.ClockDivision = TIM_CLOCKDIVISION_DIV1;
  htim5.Init.AutoReloadPreload = TIM_AUTORELOAD_PRELOAD_DISABLE;
  if (HAL_TIM_PWM_Init(&htim5) != HAL_OK)
  {
    Error_Handler();
  }
  sMasterConfig.MasterOutputTrigger = TIM_TRGO_RESET;
  sMasterConfig.MasterSlaveMode = TIM_MASTERSLAVEMODE_DISABLE;
  if (HAL_TIMEx_MasterConfigSynchronization(&htim5, &sMasterConfig) != HAL_OK)
  {
    Error_Handler();
  }
  sConfigOC.OCMode = TIM_OCMODE_PWM1;
  sConfigOC.Pulse = 0;
  sConfigOC.OCPolarity = TIM_OCPOLARITY_HIGH;
  sConfigOC.OCFastMode = TIM_OCFAST_DISABLE;
  if (HAL_TIM_PWM_ConfigChannel(&htim5, &sConfigOC, TIM_CHANNEL_1) != HAL_OK)
  {
    Error_Handler();
  }
  HAL_TIM_MspPostInit(&htim5);

}

static void MX_TIM13_Init(void)
{

  htim13.Instance = TIM13;
  htim13.Init.Prescaler = 275 - 1;
  htim13.Init.CounterMode = TIM_COUNTERMODE_UP;
  htim13.Init.Period = 1000-1;
  htim13.Init.ClockDivision = TIM_CLOCKDIVISION_DIV1;
  htim13.Init.AutoReloadPreload = TIM_AUTORELOAD_PRELOAD_ENABLE;
  if (HAL_TIM_Base_Init(&htim13) != HAL_OK)
  {
    Error_Handler();
  }

}

static void MX_USART3_UART_Init(void)
{

  huart3.Instance = USART3;
  huart3.Init.BaudRate = 115200;
  huart3.Init.WordLength = UART_WORDLENGTH_8B;
  huart3.Init.StopBits = UART_STOPBITS_1;
  huart3.Init.Parity = UART_PARITY_NONE;
  huart3.Init.Mode = UART_MODE_TX_RX;
  huart3.Init.HwFlowCtl = UART_HWCONTROL_NONE;
  huart3.Init.OverSampling = UART_OVERSAMPLING_16;
  huart3.Init.OneBitSampling = UART_ONE_BIT_SAMPLE_DISABLE;
  huart3.Init.ClockPrescaler = UART_PRESCALER_DIV1;
  huart3.AdvancedInit.AdvFeatureInit = UART_ADVFEATURE_NO_INIT;
  if (HAL_UART_Init(&huart3) != HAL_OK)
  {
    Error_Handler();
  }
  if (HAL_UARTEx_SetTxFifoThreshold(&huart3, UART_TXFIFO_THRESHOLD_1_8) != HAL_OK)
  {
    Error_Handler();
  }
  if (HAL_UARTEx_SetRxFifoThreshold(&huart3, UART_RXFIFO_THRESHOLD_1_8) != HAL_OK)
  {
    Error_Handler();
  }
  if (HAL_UARTEx_DisableFifoMode(&huart3) != HAL_OK)
  {
    Error_Handler();
  }

}

static void MX_GPIO_Init(void)
{
  GPIO_InitTypeDef GPIO_InitStruct = {0};

  /* GPIO Ports Clock Enable */
  __HAL_RCC_GPIOB_CLK_ENABLE();
  __HAL_RCC_GPIOG_CLK_ENABLE();
  __HAL_RCC_GPIOD_CLK_ENABLE();
  __HAL_RCC_GPIOA_CLK_ENABLE();
  __HAL_RCC_GPIOE_CLK_ENABLE();
  __HAL_RCC_GPIOC_CLK_ENABLE();
  __HAL_RCC_GPIOH_CLK_ENABLE();
  __HAL_RCC_GPIOF_CLK_ENABLE();

  /*Configure GPIO pin Output Level */
  HAL_GPIO_WritePin(GPIOD, Detectn_Pin|LCD_DISP_Pin, GPIO_PIN_RESET);

  /*Configure GPIO pin Output Level */
  HAL_GPIO_WritePin(GPIOE, SPI5_NSS2_Pin|STMOD_17_Pin|STMOD_19_Pin|STMOD_18_Pin, GPIO_PIN_RESET);

  /*Configure GPIO pin Output Level */
  HAL_GPIO_WritePin(GPIOG, LCD_BL_CTRL_Pin|SPI5_NSS3_Pin|MEMS_LED_Pin|ARD_D4_Pin
                          |ARD_D2_Pin, GPIO_PIN_RESET);

  /*Configure GPIO pin Output Level */
  HAL_GPIO_WritePin(GPIOF, SPI5_NSS1_Pin|STMOD_20_Pin, GPIO_PIN_RESET);

  /*Configure GPIO pin Output Level */
  HAL_GPIO_WritePin(GPIOB, GPIO_PIN_15|GPIO_PIN_14, GPIO_PIN_RESET);

  /*Configure GPIO pin Output Level */
  HAL_GPIO_WritePin(GPIOC, USER_LED2_Pin|USER_LED1_Pin, GPIO_PIN_RESET);

  /*Configure GPIO pin Output Level */
  HAL_GPIO_WritePin(LCD_RST_GPIO_Port, LCD_RST_Pin, GPIO_PIN_RESET);

  /*Configure GPIO pins : LCD_B6_Pin LCD_B7_Pin LCD_G0_Pin LCD_G1_Pin */
  GPIO_InitStruct.Pin = LCD_B6_Pin|LCD_B7_Pin|LCD_G0_Pin|LCD_G1_Pin;
  GPIO_InitStruct.Mode = GPIO_MODE_AF_PP;
  GPIO_InitStruct.Pull = GPIO_NOPULL;
  GPIO_InitStruct.Speed = GPIO_SPEED_FREQ_LOW;
  GPIO_InitStruct.Alternate = GPIO_AF14_LTDC;
  HAL_GPIO_Init(GPIOB, &GPIO_InitStruct);

  /*Configure GPIO pins : FDCAN2_TX_Pin FDCAN2_RX_Pin */
  GPIO_InitStruct.Pin = FDCAN2_TX_Pin|FDCAN2_RX_Pin;
  GPIO_InitStruct.Mode = GPIO_MODE_AF_PP;
  GPIO_InitStruct.Pull = GPIO_NOPULL;
  GPIO_InitStruct.Speed = GPIO_SPEED_FREQ_LOW;
  GPIO_InitStruct.Alternate = GPIO_AF9_FDCAN2;
  HAL_GPIO_Init(GPIOB, &GPIO_InitStruct);

  /*Configure GPIO pins : OCSPI2_IO7_Pin OCSPI2_IO5_Pin OCSPI2_IO4_Pin */
  GPIO_InitStruct.Pin = OCSPI2_IO7_Pin|OCSPI2_IO5_Pin|OCSPI2_IO4_Pin;
  GPIO_InitStruct.Mode = GPIO_MODE_AF_PP;
  GPIO_InitStruct.Pull = GPIO_NOPULL;
  GPIO_InitStruct.Speed = GPIO_SPEED_FREQ_VERY_HIGH;
  GPIO_InitStruct.Alternate = GPIO_AF9_OCTOSPIM_P2;
  HAL_GPIO_Init(GPIOG, &GPIO_InitStruct);

  /*Configure GPIO pin : OCSPI1_IO6_Pin */
  GPIO_InitStruct.Pin = OCSPI1_IO6_Pin;
  GPIO_InitStruct.Mode = GPIO_MODE_AF_PP;
  GPIO_InitStruct.Pull = GPIO_NOPULL;
  GPIO_InitStruct.Speed = GPIO_SPEED_FREQ_VERY_HIGH;
  GPIO_InitStruct.Alternate = GPIO_AF9_OCTOSPIM_P1;
  HAL_GPIO_Init(OCSPI1_IO6_GPIO_Port, &GPIO_InitStruct);

  /*Configure GPIO pins : LCD_G7_Pin LCD_B1_Pin LCD_B2_Pin */
  GPIO_InitStruct.Pin = LCD_G7_Pin|LCD_B1_Pin|LCD_B2_Pin;
  GPIO_InitStruct.Mode = GPIO_MODE_AF_PP;
  GPIO_InitStruct.Pull = GPIO_NOPULL;
  GPIO_InitStruct.Speed = GPIO_SPEED_FREQ_LOW;
  GPIO_InitStruct.Alternate = GPIO_AF14_LTDC;
  HAL_GPIO_Init(GPIOD, &GPIO_InitStruct);

  /*Configure GPIO pins : Detectn_Pin LCD_DISP_Pin */
  GPIO_InitStruct.Pin = Detectn_Pin|LCD_DISP_Pin;
  GPIO_InitStruct.Mode = GPIO_MODE_OUTPUT_PP;
  GPIO_InitStruct.Pull = GPIO_NOPULL;
  GPIO_InitStruct.Speed = GPIO_SPEED_FREQ_LOW;
  HAL_GPIO_Init(GPIOD, &GPIO_InitStruct);

  /*Configure GPIO pins : SAI4_D2_Pin SAI4_CK2_Pin */
  GPIO_InitStruct.Pin = SAI4_D2_Pin|SAI4_CK2_Pin;
  GPIO_InitStruct.Mode = GPIO_MODE_AF_PP;
  GPIO_InitStruct.Pull = GPIO_NOPULL;
  GPIO_InitStruct.Speed = GPIO_SPEED_FREQ_LOW;
  GPIO_InitStruct.Alternate = GPIO_AF10_SAI4;
  HAL_GPIO_Init(GPIOE, &GPIO_InitStruct);

  /*Configure GPIO pins : SPI5_NSS2_Pin STMOD_17_Pin STMOD_19_Pin STMOD_18_Pin */
  GPIO_InitStruct.Pin = SPI5_NSS2_Pin|STMOD_17_Pin|STMOD_19_Pin|STMOD_18_Pin;
  GPIO_InitStruct.Mode = GPIO_MODE_OUTPUT_PP;
  GPIO_InitStruct.Pull = GPIO_NOPULL;
  GPIO_InitStruct.Speed = GPIO_SPEED_FREQ_LOW;
  HAL_GPIO_Init(GPIOE, &GPIO_InitStruct);

  /*Configure GPIO pins : LCD_R0_Pin LCD_R6_Pin LCD_B4_Pin LCD_DE_Pin
                           LCD_R7_Pin LCD_G3_Pin */
  GPIO_InitStruct.Pin = LCD_R0_Pin|LCD_R6_Pin|LCD_B4_Pin|LCD_DE_Pin
                          |LCD_R7_Pin|LCD_G3_Pin;
  GPIO_InitStruct.Mode = GPIO_MODE_AF_PP;
  GPIO_InitStruct.Pull = GPIO_NOPULL;
  GPIO_InitStruct.Speed = GPIO_SPEED_FREQ_LOW;
  GPIO_InitStruct.Alternate = GPIO_AF14_LTDC;
  HAL_GPIO_Init(GPIOE, &GPIO_InitStruct);

  /*Configure GPIO pins : USB_FS_OVCR_Pin CTP_INT_Pin */
  GPIO_InitStruct.Pin = USB_FS_OVCR_Pin|CTP_INT_Pin;
  GPIO_InitStruct.Mode = GPIO_MODE_IT_RISING;
  GPIO_InitStruct.Pull = GPIO_NOPULL;
  HAL_GPIO_Init(GPIOG, &GPIO_InitStruct);

  /*Configure GPIO pins : OCSPI1_IO7_Pin OCSPI1_IO5_Pin OCSPI1_IO4_Pin */
  GPIO_InitStruct.Pin = OCSPI1_IO7_Pin|OCSPI1_IO5_Pin|OCSPI1_IO4_Pin;
  GPIO_InitStruct.Mode = GPIO_MODE_AF_PP;
  GPIO_InitStruct.Pull = GPIO_NOPULL;
  GPIO_InitStruct.Speed = GPIO_SPEED_FREQ_VERY_HIGH;
  GPIO_InitStruct.Alternate = GPIO_AF10_OCTOSPIM_P1;
  HAL_GPIO_Init(GPIOD, &GPIO_InitStruct);

  /*Configure GPIO pin : SDIO1_CMD_Pin */
  GPIO_InitStruct.Pin = SDIO1_CMD_Pin;
  GPIO_InitStruct.Mode = GPIO_MODE_AF_PP;
  GPIO_InitStruct.Pull = GPIO_NOPULL;
  GPIO_InitStruct.Speed = GPIO_SPEED_FREQ_VERY_HIGH;
  GPIO_InitStruct.Alternate = GPIO_AF12_SDMMC1;
  HAL_GPIO_Init(SDIO1_CMD_GPIO_Port, &GPIO_InitStruct);

  /*Configure GPIO pins : SDIO1_CK_Pin SDIO1_D3_Pin SDIO1_D2_Pin SDIO1_D0_Pin
                           SDIO1_D1_Pin */
  GPIO_InitStruct.Pin = SDIO1_CK_Pin|SDIO1_D3_Pin|SDIO1_D2_Pin|SDIO1_D0_Pin
                          |SDIO1_D1_Pin;
  GPIO_InitStruct.Mode = GPIO_MODE_AF_PP;
  GPIO_InitStruct.Pull = GPIO_NOPULL;
  GPIO_InitStruct.Speed = GPIO_SPEED_FREQ_VERY_HIGH;
  GPIO_InitStruct.Alternate = GPIO_AF12_SDMMC1;
  HAL_GPIO_Init(GPIOC, &GPIO_InitStruct);

  /*Configure GPIO pins : FDCAN1_RX_Pin FDCAN1_TX_Pin */
  GPIO_InitStruct.Pin = FDCAN1_RX_Pin|FDCAN1_TX_Pin;
  GPIO_InitStruct.Mode = GPIO_MODE_AF_PP;
  GPIO_InitStruct.Pull = GPIO_NOPULL;
  GPIO_InitStruct.Speed = GPIO_SPEED_FREQ_LOW;
  GPIO_InitStruct.Alternate = GPIO_AF9_FDCAN1;
  HAL_GPIO_Init(GPIOH, &GPIO_InitStruct);

  /*Configure GPIO pin : LCD_B3_Pin */
  GPIO_InitStruct.Pin = LCD_B3_Pin;
  GPIO_InitStruct.Mode = GPIO_MODE_AF_PP;
  GPIO_InitStruct.Pull = GPIO_NOPULL;
  GPIO_InitStruct.Speed = GPIO_SPEED_FREQ_LOW;
  GPIO_InitStruct.Alternate = GPIO_AF13_LTDC;
  HAL_GPIO_Init(LCD_B3_GPIO_Port, &GPIO_InitStruct);

  /*Configure GPIO pins : USB_FS_DP_Pin USB_FS_DM_Pin */
  GPIO_InitStruct.Pin = USB_FS_DP_Pin|USB_FS_DM_Pin;
  GPIO_InitStruct.Mode = GPIO_MODE_AF_PP;
  GPIO_InitStruct.Pull = GPIO_NOPULL;
  GPIO_InitStruct.Speed = GPIO_SPEED_FREQ_LOW;
  HAL_GPIO_Init(GPIOA, &GPIO_InitStruct);

  /*Configure GPIO pin : Blue_button_B2_used_for_wakeup_Pin */
  GPIO_InitStruct.Pin = Blue_button_B2_used_for_wakeup_Pin;
  GPIO_InitStruct.Mode = GPIO_MODE_INPUT;
  GPIO_InitStruct.Pull = GPIO_NOPULL;
  HAL_GPIO_Init(Blue_button_B2_used_for_wakeup_GPIO_Port, &GPIO_InitStruct);

  /*Configure GPIO pin : OCSPI1_IO2_Pin */
  GPIO_InitStruct.Pin = OCSPI1_IO2_Pin;
  GPIO_InitStruct.Mode = GPIO_MODE_AF_PP;
  GPIO_InitStruct.Pull = GPIO_NOPULL;
  GPIO_InitStruct.Speed = GPIO_SPEED_FREQ_VERY_HIGH;
  GPIO_InitStruct.Alternate = GPIO_AF9_OCTOSPIM_P1;
  HAL_GPIO_Init(OCSPI1_IO2_GPIO_Port, &GPIO_InitStruct);

  /*Configure GPIO pins : LCD_B0_Pin LCD_CLK_Pin */
  GPIO_InitStruct.Pin = LCD_B0_Pin|LCD_CLK_Pin;
  GPIO_InitStruct.Mode = GPIO_MODE_AF_PP;
  GPIO_InitStruct.Pull = GPIO_NOPULL;
  GPIO_InitStruct.Speed = GPIO_SPEED_FREQ_LOW;
  GPIO_InitStruct.Alternate = GPIO_AF14_LTDC;
  HAL_GPIO_Init(GPIOG, &GPIO_InitStruct);

  /*Configure GPIO pins : OCSPI2_IO6_Pin OCSPI2_NCS_Pin */
  GPIO_InitStruct.Pin = OCSPI2_IO6_Pin|OCSPI2_NCS_Pin;
  GPIO_InitStruct.Mode = GPIO_MODE_AF_PP;
  GPIO_InitStruct.Pull = GPIO_NOPULL;
  GPIO_InitStruct.Speed = GPIO_SPEED_FREQ_VERY_HIGH;
  GPIO_InitStruct.Alternate = GPIO_AF3_OCTOSPIM_P2;
  HAL_GPIO_Init(GPIOG, &GPIO_InitStruct);

  /*Configure GPIO pin : USB_FS_ID_Pin */
  GPIO_InitStruct.Pin = USB_FS_ID_Pin;
  GPIO_InitStruct.Mode = GPIO_MODE_AF_PP;
  GPIO_InitStruct.Pull = GPIO_NOPULL;
  GPIO_InitStruct.Speed = GPIO_SPEED_FREQ_LOW;
  GPIO_InitStruct.Alternate = GPIO_AF10_OTG1_HS;
  HAL_GPIO_Init(USB_FS_ID_GPIO_Port, &GPIO_InitStruct);

  /*Configure GPIO pins : LCD_BL_CTRL_Pin SPI5_NSS3_Pin MEMS_LED_Pin ARD_D4_Pin
                           ARD_D2_Pin */
  GPIO_InitStruct.Pin = LCD_BL_CTRL_Pin|SPI5_NSS3_Pin|MEMS_LED_Pin|ARD_D4_Pin
                          |ARD_D2_Pin;
  GPIO_InitStruct.Mode = GPIO_MODE_OUTPUT_PP;
  GPIO_InitStruct.Pull = GPIO_NOPULL;
  GPIO_InitStruct.Speed = GPIO_SPEED_FREQ_LOW;
  HAL_GPIO_Init(GPIOG, &GPIO_InitStruct);

  /*Configure GPIO pins : LCD_G4_Pin LCD_R5_Pin LCD_R3_Pin LCD_R2_Pin
                           LCD_R4_Pin LCD_R1_Pin */
  GPIO_InitStruct.Pin = LCD_G4_Pin|LCD_R5_Pin|LCD_R3_Pin|LCD_R2_Pin
                          |LCD_R4_Pin|LCD_R1_Pin;
  GPIO_InitStruct.Mode = GPIO_MODE_AF_PP;
  GPIO_InitStruct.Pull = GPIO_NOPULL;
  GPIO_InitStruct.Speed = GPIO_SPEED_FREQ_LOW;
  GPIO_InitStruct.Alternate = GPIO_AF14_LTDC;
  HAL_GPIO_Init(GPIOH, &GPIO_InitStruct);

  /*Configure GPIO pins : LCD_G6_Pin LCD_HSYNC_Pin */
  GPIO_InitStruct.Pin = LCD_G6_Pin|LCD_HSYNC_Pin;
  GPIO_InitStruct.Mode = GPIO_MODE_AF_PP;
  GPIO_InitStruct.Pull = GPIO_NOPULL;
  GPIO_InitStruct.Speed = GPIO_SPEED_FREQ_LOW;
  GPIO_InitStruct.Alternate = GPIO_AF14_LTDC;
  HAL_GPIO_Init(GPIOC, &GPIO_InitStruct);

  /*Configure GPIO pin : SAI1_SD_A_Pin */
  GPIO_InitStruct.Pin = SAI1_SD_A_Pin;
  GPIO_InitStruct.Mode = GPIO_MODE_AF_PP;
  GPIO_InitStruct.Pull = GPIO_NOPULL;
  GPIO_InitStruct.Speed = GPIO_SPEED_FREQ_LOW;
  GPIO_InitStruct.Alternate = GPIO_AF6_SAI1;
  HAL_GPIO_Init(SAI1_SD_A_GPIO_Port, &GPIO_InitStruct);

  /*Configure GPIO pins : OCSPI2_IO1_Pin OCSPI2_IO0_Pin OCSPI2_IO2_Pin OCSPI2_CLK_Pin
                           OCSPI2_IO3_Pin OCSPI2_DQS_Pin */
  GPIO_InitStruct.Pin = OCSPI2_IO1_Pin|OCSPI2_IO0_Pin|OCSPI2_IO2_Pin|OCSPI2_CLK_Pin
                          |OCSPI2_IO3_Pin|OCSPI2_DQS_Pin;
  GPIO_InitStruct.Mode = GPIO_MODE_AF_PP;
  GPIO_InitStruct.Pull = GPIO_NOPULL;
  GPIO_InitStruct.Speed = GPIO_SPEED_FREQ_VERY_HIGH;
  GPIO_InitStruct.Alternate = GPIO_AF9_OCTOSPIM_P2;
  HAL_GPIO_Init(GPIOF, &GPIO_InitStruct);

  /*Configure GPIO pins : SPI5_NSS1_Pin STMOD_20_Pin */
  GPIO_InitStruct.Pin = SPI5_NSS1_Pin|STMOD_20_Pin;
  GPIO_InitStruct.Mode = GPIO_MODE_OUTPUT_PP;
  GPIO_InitStruct.Pull = GPIO_NOPULL;
  GPIO_InitStruct.Speed = GPIO_SPEED_FREQ_LOW;
  HAL_GPIO_Init(GPIOF, &GPIO_InitStruct);

  /*Configure GPIO pin : uSD_Detect_Pin */
  GPIO_InitStruct.Pin = uSD_Detect_Pin;
  GPIO_InitStruct.Mode = GPIO_MODE_IT_RISING;
  GPIO_InitStruct.Pull = GPIO_NOPULL;
  HAL_GPIO_Init(uSD_Detect_GPIO_Port, &GPIO_InitStruct);

  /*Configure GPIO pins : OCSPI1_IO3_Pin OCSPI1_IO1_Pin */
  GPIO_InitStruct.Pin = OCSPI1_IO3_Pin|OCSPI1_IO1_Pin;
  GPIO_InitStruct.Mode = GPIO_MODE_AF_PP;
  GPIO_InitStruct.Pull = GPIO_NOPULL;
  GPIO_InitStruct.Speed = GPIO_SPEED_FREQ_VERY_HIGH;
  GPIO_InitStruct.Alternate = GPIO_AF9_OCTOSPIM_P1;
  HAL_GPIO_Init(GPIOD, &GPIO_InitStruct);

  /*Configure GPIO pins : PB15 PB14 */
  GPIO_InitStruct.Pin = GPIO_PIN_15|GPIO_PIN_14;
  GPIO_InitStruct.Mode = GPIO_MODE_OUTPUT_PP;
  GPIO_InitStruct.Pull = GPIO_NOPULL;
  GPIO_InitStruct.Speed = GPIO_SPEED_FREQ_LOW;
  HAL_GPIO_Init(GPIOB, &GPIO_InitStruct);

  /*Configure GPIO pins : RMII_MDC_Pin RMII_RXD1_Pin RMII_RXD0_Pin */
  GPIO_InitStruct.Pin = RMII_MDC_Pin|RMII_RXD1_Pin|RMII_RXD0_Pin;
  GPIO_InitStruct.Mode = GPIO_MODE_AF_PP;
  GPIO_InitStruct.Pull = GPIO_NOPULL;
  GPIO_InitStruct.Speed = GPIO_SPEED_FREQ_LOW;
  GPIO_InitStruct.Alternate = GPIO_AF11_ETH;
  HAL_GPIO_Init(GPIOC, &GPIO_InitStruct);

  /*Configure GPIO pins : RMII_TXD1_Pin RMII_TXD0_Pin RMII_RX_ER_Pin RMII_TX_EN_Pin */
  GPIO_InitStruct.Pin = RMII_TXD1_Pin|RMII_TXD0_Pin|RMII_RX_ER_Pin|RMII_TX_EN_Pin;
  GPIO_InitStruct.Mode = GPIO_MODE_AF_PP;
  GPIO_InitStruct.Pull = GPIO_NOPULL;
  GPIO_InitStruct.Speed = GPIO_SPEED_FREQ_LOW;
  GPIO_InitStruct.Alternate = GPIO_AF11_ETH;
  HAL_GPIO_Init(GPIOB, &GPIO_InitStruct);

  /*Configure GPIO pins : USER_LED2_Pin USER_LED1_Pin */
  GPIO_InitStruct.Pin = USER_LED2_Pin|USER_LED1_Pin;
  GPIO_InitStruct.Mode = GPIO_MODE_OUTPUT_PP;
  GPIO_InitStruct.Pull = GPIO_NOPULL;
  GPIO_InitStruct.Speed = GPIO_SPEED_FREQ_LOW;
  HAL_GPIO_Init(GPIOC, &GPIO_InitStruct);

  /*Configure GPIO pins : LCD_B5_Pin LCD_VSYNC_Pin LCD_G2_Pin */
  GPIO_InitStruct.Pin = LCD_B5_Pin|LCD_VSYNC_Pin|LCD_G2_Pin;
  GPIO_InitStruct.Mode = GPIO_MODE_AF_PP;
  GPIO_InitStruct.Pull = GPIO_NOPULL;
  GPIO_InitStruct.Speed = GPIO_SPEED_FREQ_LOW;
  GPIO_InitStruct.Alternate = GPIO_AF14_LTDC;
  HAL_GPIO_Init(GPIOA, &GPIO_InitStruct);

  /*Configure GPIO pins : RMII_CRS_DV_Pin RMII_REF_CLK_Pin RMII_MDIO_Pin */
  GPIO_InitStruct.Pin = RMII_CRS_DV_Pin|RMII_REF_CLK_Pin|RMII_MDIO_Pin;
  GPIO_InitStruct.Mode = GPIO_MODE_AF_PP;
  GPIO_InitStruct.Pull = GPIO_NOPULL;
  GPIO_InitStruct.Speed = GPIO_SPEED_FREQ_LOW;
  GPIO_InitStruct.Alternate = GPIO_AF11_ETH;
  HAL_GPIO_Init(GPIOA, &GPIO_InitStruct);

  /*Configure GPIO pin : Audio_Int_Pin */
  GPIO_InitStruct.Pin = Audio_Int_Pin;
  GPIO_InitStruct.Mode = GPIO_MODE_IT_RISING;
  GPIO_InitStruct.Pull = GPIO_NOPULL;
  HAL_GPIO_Init(Audio_Int_GPIO_Port, &GPIO_InitStruct);

  /*Configure GPIO pin : STMOD_11_INT_Pin */
  GPIO_InitStruct.Pin = STMOD_11_INT_Pin;
  GPIO_InitStruct.Mode = GPIO_MODE_IT_RISING;
  GPIO_InitStruct.Pull = GPIO_NOPULL;
  HAL_GPIO_Init(STMOD_11_INT_GPIO_Port, &GPIO_InitStruct);

  /*Configure GPIO pin : LCD_G5_Pin */
  GPIO_InitStruct.Pin = LCD_G5_Pin;
  GPIO_InitStruct.Mode = GPIO_MODE_AF_PP;
  GPIO_InitStruct.Pull = GPIO_NOPULL;
  GPIO_InitStruct.Speed = GPIO_SPEED_FREQ_LOW;
  GPIO_InitStruct.Alternate = GPIO_AF9_LTDC;
  HAL_GPIO_Init(LCD_G5_GPIO_Port, &GPIO_InitStruct);

  /*Configure GPIO pin : OCSPI1_DQS_Pin */
  GPIO_InitStruct.Pin = OCSPI1_DQS_Pin;
  GPIO_InitStruct.Mode = GPIO_MODE_AF_PP;
  GPIO_InitStruct.Pull = GPIO_NOPULL;
  GPIO_InitStruct.Speed = GPIO_SPEED_FREQ_VERY_HIGH;
  GPIO_InitStruct.Alternate = GPIO_AF10_OCTOSPIM_P1;
  HAL_GPIO_Init(OCSPI1_DQS_GPIO_Port, &GPIO_InitStruct);

  /*Configure GPIO pin : LCD_RST_Pin */
  GPIO_InitStruct.Pin = LCD_RST_Pin;
  GPIO_InitStruct.Mode = GPIO_MODE_OUTPUT_PP;
  GPIO_InitStruct.Pull = GPIO_NOPULL;
  GPIO_InitStruct.Speed = GPIO_SPEED_FREQ_LOW;
  HAL_GPIO_Init(LCD_RST_GPIO_Port, &GPIO_InitStruct);

}

void Error_Handler(void)
{
  __disable_irq();
  while (1)
  {
  }
}

/************************ (C) COPYRIGHT STMicroelectronics *****END OF FILE****/
